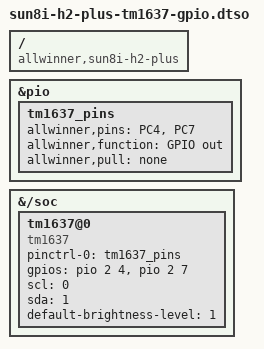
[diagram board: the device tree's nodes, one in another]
/dts-v1/;
/plugin/;

/ {
    compatible = "allwinner,sun8i-h2-plus";
};

&pio {
    tm1637_pins: tm1637_pins {
	allwinner,pins = "PC4", "PC7";
	allwinner,function = "GPIO out"; // out (initially)
	allwinner,pull = "none";
    };
};

&{/soc} {
    tm1637@0 {
	compatible = "tm1637";
	pinctrl-names = "default";
	pinctrl-0 = <&tm1637_pins>;
	gpios = <&pio 2 4 0
	         &pio 2 7 0>;
	scl = <0>; // PC4 (16)
	sda = <1>; // PC7 (18)

	/* From 0 to 7. 0 is a darkest */
	default-brightness-level = <1>;

	/* Uncomment for a bytes of segments input
	 * A human readable string, otherwise */
	//raw-mode;

	status = "okay";
    };
};
